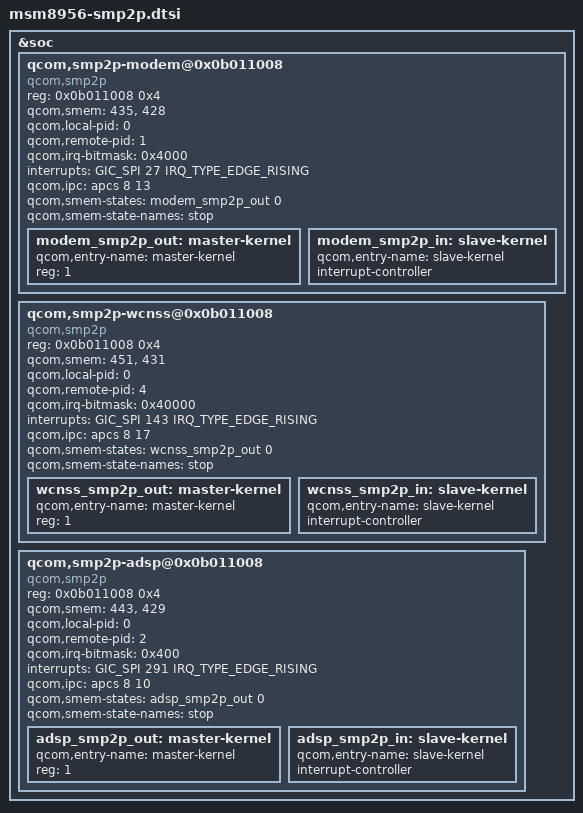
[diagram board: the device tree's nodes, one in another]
/* Copyright (c) 2015, The Linux Foundation. All rights reserved.
 *
 * This program is free software; you can redistribute it and/or modify
 * it under the terms of the GNU General Public License version 2 and
 * only version 2 as published by the Free Software Foundation.
 *
 * This program is distributed in the hope that it will be useful,
 * but WITHOUT ANY WARRANTY; without even the implied warranty of
 * MERCHANTABILITY or FITNESS FOR A PARTICULAR PURPOSE.  See the
 * GNU General Public License for more details.
 */
&soc {
	qcom,smp2p-modem@0x0b011008 {
		compatible = "qcom,smp2p";
		reg = <0x0b011008 0x4>;
		qcom,smem = <435>, <428>;
		qcom,local-pid = <0>;
		qcom,remote-pid = <1>;
		qcom,irq-bitmask = <0x4000>;
		interrupts = <GIC_SPI 27 IRQ_TYPE_EDGE_RISING>;
		qcom,ipc = <&apcs 8 13>;

		qcom,smem-states = <&modem_smp2p_out 0>;
		qcom,smem-state-names = "stop";

		#address-cells = <1>;
		#size-cells = <0>;

		modem_smp2p_out: master-kernel {
			qcom,entry-name = "master-kernel";
			#qcom,smem-state-cells = <1>;
			reg = <1>;
		};

		modem_smp2p_in: slave-kernel {
			qcom,entry-name = "slave-kernel";

			interrupt-controller;
			#interrupt-cells = <2>;
		};
	};

	qcom,smp2p-wcnss@0x0b011008 {
		compatible = "qcom,smp2p";
		reg = <0x0b011008 0x4>;
		qcom,smem = <451>, <431>;
		qcom,local-pid = <0>;
		qcom,remote-pid = <4>;
		qcom,irq-bitmask = <0x40000>;
		interrupts = <GIC_SPI 143 IRQ_TYPE_EDGE_RISING>;
		qcom,ipc = <&apcs 8 17>;

		qcom,smem-states = <&wcnss_smp2p_out 0>;
		qcom,smem-state-names = "stop";

		#address-cells = <1>;
		#size-cells = <0>;

		wcnss_smp2p_out: master-kernel {
			qcom,entry-name = "master-kernel";
			#qcom,smem-state-cells = <1>;
			reg = <1>;
		};

		wcnss_smp2p_in: slave-kernel {
			qcom,entry-name = "slave-kernel";

			interrupt-controller;
			#interrupt-cells = <2>;
		};
	};

	qcom,smp2p-adsp@0x0b011008 {
		compatible = "qcom,smp2p";
		reg = <0x0b011008 0x4>;
		qcom,smem = <443>, <429>;
		qcom,local-pid = <0>;
		qcom,remote-pid = <2>;
		qcom,irq-bitmask = <0x400>;
		interrupts = <GIC_SPI 291 IRQ_TYPE_EDGE_RISING>;
		qcom,ipc = <&apcs 8 10>;

		qcom,smem-states = <&adsp_smp2p_out 0>;
		qcom,smem-state-names = "stop";

		#address-cells = <1>;
		#size-cells = <0>;

		adsp_smp2p_out: master-kernel {
			qcom,entry-name = "master-kernel";
			#qcom,smem-state-cells = <1>;
			reg = <1>;
		};

		adsp_smp2p_in: slave-kernel {
			qcom,entry-name = "slave-kernel";

			interrupt-controller;
			#interrupt-cells = <2>;
		};
	};
};
